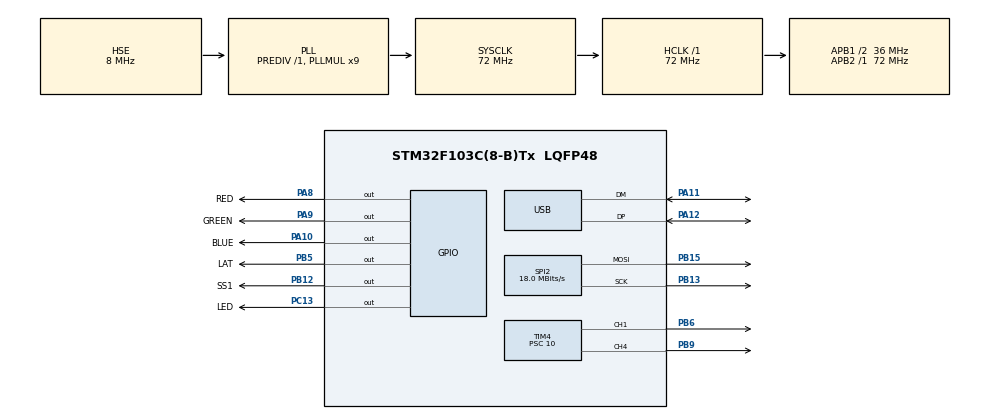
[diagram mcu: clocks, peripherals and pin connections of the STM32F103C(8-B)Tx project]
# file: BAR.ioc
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Dma.MEMTOMEM.0.Direction=DMA_MEMORY_TO_MEMORY
Dma.MEMTOMEM.0.Instance=DMA1_Channel6
Dma.MEMTOMEM.0.MemDataAlignment=DMA_MDATAALIGN_BYTE
Dma.MEMTOMEM.0.MemInc=DMA_MINC_ENABLE
Dma.MEMTOMEM.0.Mode=DMA_NORMAL
Dma.MEMTOMEM.0.PeriphDataAlignment=DMA_PDATAALIGN_BYTE
Dma.MEMTOMEM.0.PeriphInc=DMA_PINC_ENABLE
Dma.MEMTOMEM.0.Priority=DMA_PRIORITY_LOW
Dma.MEMTOMEM.1.Direction=DMA_MEMORY_TO_MEMORY
Dma.MEMTOMEM.1.Instance=DMA1_Channel4
Dma.MEMTOMEM.1.MemDataAlignment=DMA_MDATAALIGN_BYTE
Dma.MEMTOMEM.1.MemInc=DMA_MINC_ENABLE
Dma.MEMTOMEM.1.Mode=DMA_NORMAL
Dma.MEMTOMEM.1.PeriphDataAlignment=DMA_PDATAALIGN_BYTE
Dma.MEMTOMEM.1.PeriphInc=DMA_PINC_ENABLE
Dma.MEMTOMEM.1.Priority=DMA_PRIORITY_LOW
Dma.MEMTOMEM.2.Direction=DMA_MEMORY_TO_MEMORY
Dma.MEMTOMEM.2.Instance=DMA1_Channel1
Dma.MEMTOMEM.2.MemDataAlignment=DMA_MDATAALIGN_BYTE
Dma.MEMTOMEM.2.MemInc=DMA_MINC_ENABLE
Dma.MEMTOMEM.2.Mode=DMA_NORMAL
Dma.MEMTOMEM.2.PeriphDataAlignment=DMA_PDATAALIGN_BYTE
Dma.MEMTOMEM.2.PeriphInc=DMA_PINC_ENABLE
Dma.MEMTOMEM.2.Priority=DMA_PRIORITY_LOW
Dma.MEMTOMEM.3.Direction=DMA_MEMORY_TO_MEMORY
Dma.MEMTOMEM.3.Instance=DMA1_Channel7
Dma.MEMTOMEM.3.MemDataAlignment=DMA_MDATAALIGN_BYTE
Dma.MEMTOMEM.3.MemInc=DMA_MINC_ENABLE
Dma.MEMTOMEM.3.Mode=DMA_NORMAL
Dma.MEMTOMEM.3.PeriphDataAlignment=DMA_PDATAALIGN_BYTE
Dma.MEMTOMEM.3.PeriphInc=DMA_PINC_ENABLE
Dma.MEMTOMEM.3.Priority=DMA_PRIORITY_LOW
Dma.Request0=MEMTOMEM
Dma.Request1=MEMTOMEM
Dma.Request2=MEMTOMEM
Dma.Request3=MEMTOMEM
Dma.Request4=SPI2_TX
Dma.SPI2_TX.4.Direction=DMA_MEMORY_TO_PERIPH
Dma.SPI2_TX.4.Instance=DMA1_Channel5
Dma.SPI2_TX.4.MemDataAlignment=DMA_MDATAALIGN_BYTE
Dma.SPI2_TX.4.MemInc=DMA_MINC_ENABLE
Dma.SPI2_TX.4.Mode=DMA_NORMAL
Dma.SPI2_TX.4.PeriphDataAlignment=DMA_PDATAALIGN_BYTE
Dma.SPI2_TX.4.PeriphInc=DMA_PINC_DISABLE
Dma.SPI2_TX.4.Priority=DMA_PRIORITY_VERY_HIGH
Mcu.Family=STM32F1
Mcu.Name=STM32F103C(8-B)Tx
Mcu.Package=LQFP48
NVIC.DMA1_Channel5_IRQn=true\:0\:0\:false\:false\:true\:false\:true
NVIC.PriorityGroup=NVIC_PRIORITYGROUP_4
NVIC.SPI2_IRQn=true\:0\:0\:false\:false\:true\:true\:true
NVIC.TIM2_IRQn=true\:1\:0\:true\:false\:true\:true\:true
NVIC.TIM3_IRQn=true\:3\:0\:true\:false\:true\:true\:true
NVIC.USB_LP_CAN1_RX0_IRQn=true\:2\:0\:true\:false\:true\:false\:true
PA10.GPIO_Label=BLUE
PA10.Signal=GPIO_Output
PA11.Mode=Device
PA11.Signal=USB_DM
PA12.Mode=Device
PA12.Signal=USB_DP
PA13.Mode=Serial_Wire
PA13.Signal=SYS_JTMS-SWDIO
PA14.Mode=Serial_Wire
PA14.Signal=SYS_JTCK-SWCLK
PA8.GPIO_Label=RED
PA8.GPIO_PuPd=GPIO_PULLUP
PA8.GPIO_Speed=GPIO_SPEED_FREQ_HIGH
PA8.PinState=GPIO_PIN_RESET
PA8.Signal=GPIO_Output
PA9.GPIO_Label=GREEN
PA9.Signal=GPIO_Output
PB12.GPIO_Label=SS1
PB12.GPIO_PuPd=GPIO_PULLUP
PB12.Signal=GPIO_Output
PB13.Mode=TX_Only_Simplex_Unidirect_Master
PB13.Signal=SPI2_SCK
PB15.Mode=TX_Only_Simplex_Unidirect_Master
PB15.Signal=SPI2_MOSI
PB5.GPIO_Label=LAT
PB5.GPIO_PuPd=GPIO_PULLUP
PB5.GPIO_Speed=GPIO_SPEED_FREQ_LOW
PB5.Signal=GPIO_Output
PB6.Signal=S_TIM4_CH1
PB9.Signal=S_TIM4_CH4
PC13-TAMPER-RTC.GPIO_Label=LED
PC13-TAMPER-RTC.GPIO_PuPd=GPIO_PULLUP
PC13-TAMPER-RTC.PinState=GPIO_PIN_SET
PC13-TAMPER-RTC.Signal=GPIO_Output
PC14-OSC32_IN.Mode=LSE-External-Oscillator
PC14-OSC32_IN.Signal=RCC_OSC32_IN
PC15-OSC32_OUT.Mode=LSE-External-Oscillator
PC15-OSC32_OUT.Signal=RCC_OSC32_OUT
PD0-OSC_IN.Mode=HSE-External-Oscillator
PD0-OSC_IN.Signal=RCC_OSC_IN
PD1-OSC_OUT.Mode=HSE-External-Oscillator
PD1-OSC_OUT.Signal=RCC_OSC_OUT
ProjectManager.HeapSize=0x200
ProjectManager.StackSize=0x400
ProjectManager.TargetToolchain=STM32CubeIDE
RCC.AHBFreq_Value=72000000
RCC.APB1CLKDivider=RCC_HCLK_DIV2
RCC.APB1Freq_Value=36000000
RCC.APB1TimFreq_Value=72000000
RCC.APB2Freq_Value=72000000
RCC.APB2TimFreq_Value=72000000
RCC.HCLKFreq_Value=72000000
RCC.PLLMUL=RCC_PLL_MUL9
RCC.PLLSourceVirtual=RCC_PLLSOURCE_HSE
RCC.SYSCLKFreq_VALUE=72000000
RCC.SYSCLKSource=RCC_SYSCLKSOURCE_PLLCLK
RCC.USBFreq_Value=48000000
RCC.USBPrescaler=RCC_USBCLKSOURCE_PLL_DIV1_5
SH.S_TIM4_CH1.0=TIM4_CH1,PWM Generation1 CH1
SH.S_TIM4_CH4.0=TIM4_CH4,PWM Generation4 CH4
SPI2.CalculateBaudRate=18.0 MBits/s
SPI2.Direction=SPI_DIRECTION_2LINES
SPI2.Mode=SPI_MODE_MASTER
SPI2.VirtualType=VM_MASTER
TIM2.AutoReloadPreload=TIM_AUTORELOAD_PRELOAD_ENABLE
TIM2.ClockDivision=TIM_CLOCKDIVISION_DIV2
TIM2.Period=1366
TIM2.Prescaler=36
TIM3.AutoReloadPreload=TIM_AUTORELOAD_PRELOAD_ENABLE
TIM3.ClockDivision=TIM_CLOCKDIVISION_DIV2
TIM3.Period=10000
TIM3.Prescaler=3600
TIM4.AutoReloadPreload=TIM_AUTORELOAD_PRELOAD_DISABLE
TIM4.Channel-PWM\ Generation1\ CH1=TIM_CHANNEL_1
TIM4.Channel-PWM\ Generation4\ CH4=TIM_CHANNEL_4
TIM4.ClockDivision=TIM_CLOCKDIVISION_DIV2
TIM4.Period=254
TIM4.Prescaler=10
USB_DEVICE.CLASS_NAME_FS=CDC
USB_DEVICE.MANUFACTURER_STRING=dESIGNED bY @GiaLu 
USB_DEVICE.PRODUCT_STRING_CDC_FS=GiaLu
USB_DEVICE.VirtualMode=Cdc
USB_DEVICE.VirtualModeFS=Cdc_FS
VP_TIM2_VS_ClockSourceINT.Mode=Internal
VP_TIM3_VS_ClockSourceINT.Mode=Internal
VP_TIM4_VS_ClockSourceINT.Mode=Internal
VP_USB_DEVICE_VS_USB_DEVICE_CDC_FS.Mode=CDC_FS
board=custom

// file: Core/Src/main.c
/* USER CODE BEGIN Header */
/**
  ******************************************************************************
  * @file           : main.c
  * @brief          : Main program body
  ******************************************************************************
  * @attention
  *
  * <h2><center>&copy; Copyright (c) 2021 STMicroelectronics.
  * All rights reserved.</center></h2>
  *
  * This software component is licensed by ST under BSD 3-Clause license,
  * the "License"; You may not use this file except in compliance with the
  * License. You may obtain a copy of the License at:
  *                        opensource.org/licenses/BSD-3-Clause
  *
  ******************************************************************************
  */
/* USER CODE END Header */
#include "main.h"
#include "usb_device.h"

/* USER CODE BEGIN Includes */
#include "bar.h"
/* USER CODE END Includes */

SPI_HandleTypeDef hspi2;
DMA_HandleTypeDef hdma_spi2_tx;

TIM_HandleTypeDef htim2;
TIM_HandleTypeDef htim3;
TIM_HandleTypeDef htim4;

DMA_HandleTypeDef hdma_memtomem_dma1_channel6;
DMA_HandleTypeDef hdma_memtomem_dma1_channel4;
DMA_HandleTypeDef hdma_memtomem_dma1_channel1;
DMA_HandleTypeDef hdma_memtomem_dma1_channel7;

void SystemClock_Config(void);
static void MX_GPIO_Init(void);
static void MX_DMA_Init(void);
static void MX_SPI2_Init(void);
static void MX_TIM2_Init(void);
static void MX_TIM3_Init(void);
static void MX_TIM4_Init(void);

int main(void)
{

  /* MCU Configuration--------------------------------------------------------*/

  /* Reset of all peripherals, Initializes the Flash interface and the Systick. */
  HAL_Init();

  /* Configure the system clock */
  SystemClock_Config();

  /* Initialize all configured peripherals */
  MX_GPIO_Init();
  MX_DMA_Init();
  MX_SPI2_Init();
  MX_TIM2_Init();
  MX_TIM3_Init();
  MX_TIM4_Init();
  MX_USB_DEVICE_Init();

  /* Infinite loop */
  while (1)
  {

    /* USER CODE BEGIN 3 */

	  _run();
  }
  /* USER CODE END 3 */
}

void SystemClock_Config(void)
{
  RCC_OscInitTypeDef RCC_OscInitStruct = {0};
  RCC_ClkInitTypeDef RCC_ClkInitStruct = {0};
  RCC_PeriphCLKInitTypeDef PeriphClkInit = {0};

  /** Initializes the RCC Oscillators according to the specified parameters
  * in the RCC_OscInitTypeDef structure.
  */
  RCC_OscInitStruct.OscillatorType = RCC_OSCILLATORTYPE_HSE;
  RCC_OscInitStruct.HSEState = RCC_HSE_ON;
  RCC_OscInitStruct.HSEPredivValue = RCC_HSE_PREDIV_DIV1;
  RCC_OscInitStruct.HSIState = RCC_HSI_ON;
  RCC_OscInitStruct.PLL.PLLState = RCC_PLL_ON;
  RCC_OscInitStruct.PLL.PLLSource = RCC_PLLSOURCE_HSE;
  RCC_OscInitStruct.PLL.PLLMUL = RCC_PLL_MUL9;
  if (HAL_RCC_OscConfig(&RCC_OscInitStruct) != HAL_OK)
  {
    Error_Handler();
  }
  /** Initializes the CPU, AHB and APB buses clocks
  */
  RCC_ClkInitStruct.ClockType = RCC_CLOCKTYPE_HCLK|RCC_CLOCKTYPE_SYSCLK
                              |RCC_CLOCKTYPE_PCLK1|RCC_CLOCKTYPE_PCLK2;
  RCC_ClkInitStruct.SYSCLKSource = RCC_SYSCLKSOURCE_PLLCLK;
  RCC_ClkInitStruct.AHBCLKDivider = RCC_SYSCLK_DIV1;
  RCC_ClkInitStruct.APB1CLKDivider = RCC_HCLK_DIV2;
  RCC_ClkInitStruct.APB2CLKDivider = RCC_HCLK_DIV1;

  if (HAL_RCC_ClockConfig(&RCC_ClkInitStruct, FLASH_LATENCY_2) != HAL_OK)
  {
    Error_Handler();
  }
  PeriphClkInit.PeriphClockSelection = RCC_PERIPHCLK_USB;
  PeriphClkInit.UsbClockSelection = RCC_USBCLKSOURCE_PLL_DIV1_5;
  if (HAL_RCCEx_PeriphCLKConfig(&PeriphClkInit) != HAL_OK)
  {
    Error_Handler();
  }
}

static void MX_SPI2_Init(void)
{

  /* SPI2 parameter configuration*/
  hspi2.Instance = SPI2;
  hspi2.Init.Mode = SPI_MODE_MASTER;
  hspi2.Init.Direction = SPI_DIRECTION_2LINES;
  hspi2.Init.DataSize = SPI_DATASIZE_8BIT;
  hspi2.Init.CLKPolarity = SPI_POLARITY_LOW;
  hspi2.Init.CLKPhase = SPI_PHASE_1EDGE;
  hspi2.Init.NSS = SPI_NSS_SOFT;
  hspi2.Init.BaudRatePrescaler = SPI_BAUDRATEPRESCALER_2;
  hspi2.Init.FirstBit = SPI_FIRSTBIT_MSB;
  hspi2.Init.TIMode = SPI_TIMODE_DISABLE;
  hspi2.Init.CRCCalculation = SPI_CRCCALCULATION_DISABLE;
  hspi2.Init.CRCPolynomial = 10;
  if (HAL_SPI_Init(&hspi2) != HAL_OK)
  {
    Error_Handler();
  }

}

static void MX_TIM2_Init(void)
{

  TIM_ClockConfigTypeDef sClockSourceConfig = {0};
  TIM_MasterConfigTypeDef sMasterConfig = {0};

  htim2.Instance = TIM2;
  htim2.Init.Prescaler = 36;
  htim2.Init.CounterMode = TIM_COUNTERMODE_UP;
  htim2.Init.Period = 1366;
  htim2.Init.ClockDivision = TIM_CLOCKDIVISION_DIV2;
  htim2.Init.AutoReloadPreload = TIM_AUTORELOAD_PRELOAD_ENABLE;
  if (HAL_TIM_Base_Init(&htim2) != HAL_OK)
  {
    Error_Handler();
  }
  sClockSourceConfig.ClockSource = TIM_CLOCKSOURCE_INTERNAL;
  if (HAL_TIM_ConfigClockSource(&htim2, &sClockSourceConfig) != HAL_OK)
  {
    Error_Handler();
  }
  sMasterConfig.MasterOutputTrigger = TIM_TRGO_RESET;
  sMasterConfig.MasterSlaveMode = TIM_MASTERSLAVEMODE_DISABLE;
  if (HAL_TIMEx_MasterConfigSynchronization(&htim2, &sMasterConfig) != HAL_OK)
  {
    Error_Handler();
  }

}

static void MX_TIM3_Init(void)
{

  TIM_ClockConfigTypeDef sClockSourceConfig = {0};
  TIM_MasterConfigTypeDef sMasterConfig = {0};

  htim3.Instance = TIM3;
  htim3.Init.Prescaler = 3600;
  htim3.Init.CounterMode = TIM_COUNTERMODE_UP;
  htim3.Init.Period = 10000;
  htim3.Init.ClockDivision = TIM_CLOCKDIVISION_DIV2;
  htim3.Init.AutoReloadPreload = TIM_AUTORELOAD_PRELOAD_ENABLE;
  if (HAL_TIM_Base_Init(&htim3) != HAL_OK)
  {
    Error_Handler();
  }
  sClockSourceConfig.ClockSource = TIM_CLOCKSOURCE_INTERNAL;
  if (HAL_TIM_ConfigClockSource(&htim3, &sClockSourceConfig) != HAL_OK)
  {
    Error_Handler();
  }
  sMasterConfig.MasterOutputTrigger = TIM_TRGO_RESET;
  sMasterConfig.MasterSlaveMode = TIM_MASTERSLAVEMODE_DISABLE;
  if (HAL_TIMEx_MasterConfigSynchronization(&htim3, &sMasterConfig) != HAL_OK)
  {
    Error_Handler();
  }

}

static void MX_TIM4_Init(void)
{

  TIM_ClockConfigTypeDef sClockSourceConfig = {0};
  TIM_MasterConfigTypeDef sMasterConfig = {0};
  TIM_OC_InitTypeDef sConfigOC = {0};

  htim4.Instance = TIM4;
  htim4.Init.Prescaler = 10;
  htim4.Init.CounterMode = TIM_COUNTERMODE_UP;
  htim4.Init.Period = 254;
  htim4.Init.ClockDivision = TIM_CLOCKDIVISION_DIV2;
  htim4.Init.AutoReloadPreload = TIM_AUTORELOAD_PRELOAD_DISABLE;
  if (HAL_TIM_Base_Init(&htim4) != HAL_OK)
  {
    Error_Handler();
  }
  sClockSourceConfig.ClockSource = TIM_CLOCKSOURCE_INTERNAL;
  if (HAL_TIM_ConfigClockSource(&htim4, &sClockSourceConfig) != HAL_OK)
  {
    Error_Handler();
  }
  if (HAL_TIM_PWM_Init(&htim4) != HAL_OK)
  {
    Error_Handler();
  }
  sMasterConfig.MasterOutputTrigger = TIM_TRGO_RESET;
  sMasterConfig.MasterSlaveMode = TIM_MASTERSLAVEMODE_DISABLE;
  if (HAL_TIMEx_MasterConfigSynchronization(&htim4, &sMasterConfig) != HAL_OK)
  {
    Error_Handler();
  }
  sConfigOC.OCMode = TIM_OCMODE_PWM1;
  sConfigOC.Pulse = 0;
  sConfigOC.OCPolarity = TIM_OCPOLARITY_HIGH;
  sConfigOC.OCFastMode = TIM_OCFAST_DISABLE;
  if (HAL_TIM_PWM_ConfigChannel(&htim4, &sConfigOC, TIM_CHANNEL_1) != HAL_OK)
  {
    Error_Handler();
  }
  if (HAL_TIM_PWM_ConfigChannel(&htim4, &sConfigOC, TIM_CHANNEL_4) != HAL_OK)
  {
    Error_Handler();
  }
  HAL_TIM_MspPostInit(&htim4);

}

static void MX_DMA_Init(void)
{

  /* DMA controller clock enable */
  __HAL_RCC_DMA1_CLK_ENABLE();

  /* Configure DMA request hdma_memtomem_dma1_channel6 on DMA1_Channel6 */
  hdma_memtomem_dma1_channel6.Instance = DMA1_Channel6;
  hdma_memtomem_dma1_channel6.Init.Direction = DMA_MEMORY_TO_MEMORY;
  hdma_memtomem_dma1_channel6.Init.PeriphInc = DMA_PINC_ENABLE;
  hdma_memtomem_dma1_channel6.Init.MemInc = DMA_MINC_ENABLE;
  hdma_memtomem_dma1_channel6.Init.PeriphDataAlignment = DMA_PDATAALIGN_BYTE;
  hdma_memtomem_dma1_channel6.Init.MemDataAlignment = DMA_MDATAALIGN_BYTE;
  hdma_memtomem_dma1_channel6.Init.Mode = DMA_NORMAL;
  hdma_memtomem_dma1_channel6.Init.Priority = DMA_PRIORITY_LOW;
  if (HAL_DMA_Init(&hdma_memtomem_dma1_channel6) != HAL_OK)
  {
    Error_Handler( );
  }

  /* Configure DMA request hdma_memtomem_dma1_channel4 on DMA1_Channel4 */
  hdma_memtomem_dma1_channel4.Instance = DMA1_Channel4;
  hdma_memtomem_dma1_channel4.Init.Direction = DMA_MEMORY_TO_MEMORY;
  hdma_memtomem_dma1_channel4.Init.PeriphInc = DMA_PINC_ENABLE;
  hdma_memtomem_dma1_channel4.Init.MemInc = DMA_MINC_ENABLE;
  hdma_memtomem_dma1_channel4.Init.PeriphDataAlignment = DMA_PDATAALIGN_BYTE;
  hdma_memtomem_dma1_channel4.Init.MemDataAlignment = DMA_MDATAALIGN_BYTE;
  hdma_memtomem_dma1_channel4.Init.Mode = DMA_NORMAL;
  hdma_memtomem_dma1_channel4.Init.Priority = DMA_PRIORITY_LOW;
  if (HAL_DMA_Init(&hdma_memtomem_dma1_channel4) != HAL_OK)
  {
    Error_Handler( );
  }

  /* Configure DMA request hdma_memtomem_dma1_channel1 on DMA1_Channel1 */
  hdma_memtomem_dma1_channel1.Instance = DMA1_Channel1;
  hdma_memtomem_dma1_channel1.Init.Direction = DMA_MEMORY_TO_MEMORY;
  hdma_memtomem_dma1_channel1.Init.PeriphInc = DMA_PINC_ENABLE;
  hdma_memtomem_dma1_channel1.Init.MemInc = DMA_MINC_ENABLE;
  hdma_memtomem_dma1_channel1.Init.PeriphDataAlignment = DMA_PDATAALIGN_BYTE;
  hdma_memtomem_dma1_channel1.Init.MemDataAlignment = DMA_MDATAALIGN_BYTE;
  hdma_memtomem_dma1_channel1.Init.Mode = DMA_NORMAL;
  hdma_memtomem_dma1_channel1.Init.Priority = DMA_PRIORITY_LOW;
  if (HAL_DMA_Init(&hdma_memtomem_dma1_channel1) != HAL_OK)
  {
    Error_Handler( );
  }

  /* Configure DMA request hdma_memtomem_dma1_channel7 on DMA1_Channel7 */
  hdma_memtomem_dma1_channel7.Instance = DMA1_Channel7;
  hdma_memtomem_dma1_channel7.Init.Direction = DMA_MEMORY_TO_MEMORY;
  hdma_memtomem_dma1_channel7.Init.PeriphInc = DMA_PINC_ENABLE;
  hdma_memtomem_dma1_channel7.Init.MemInc = DMA_MINC_ENABLE;
  hdma_memtomem_dma1_channel7.Init.PeriphDataAlignment = DMA_PDATAALIGN_BYTE;
  hdma_memtomem_dma1_channel7.Init.MemDataAlignment = DMA_MDATAALIGN_BYTE;
  hdma_memtomem_dma1_channel7.Init.Mode = DMA_NORMAL;
  hdma_memtomem_dma1_channel7.Init.Priority = DMA_PRIORITY_LOW;
  if (HAL_DMA_Init(&hdma_memtomem_dma1_channel7) != HAL_OK)
  {
    Error_Handler( );
  }

  /* DMA interrupt init */
  /* DMA1_Channel5_IRQn interrupt configuration */
  HAL_NVIC_SetPriority(DMA1_Channel5_IRQn, 0, 0);
  HAL_NVIC_EnableIRQ(DMA1_Channel5_IRQn);

}

static void MX_GPIO_Init(void)
{
  GPIO_InitTypeDef GPIO_InitStruct = {0};

  /* GPIO Ports Clock Enable */
  __HAL_RCC_GPIOC_CLK_ENABLE();
  __HAL_RCC_GPIOD_CLK_ENABLE();
  __HAL_RCC_GPIOB_CLK_ENABLE();
  __HAL_RCC_GPIOA_CLK_ENABLE();

  /*Configure GPIO pin Output Level */
  HAL_GPIO_WritePin(LED_GPIO_Port, LED_Pin, GPIO_PIN_SET);

  /*Configure GPIO pin Output Level */
  HAL_GPIO_WritePin(GPIOB, SS1_Pin|LAT_Pin, GPIO_PIN_RESET);

  /*Configure GPIO pin Output Level */
  HAL_GPIO_WritePin(GPIOA, RED_Pin|GREEN_Pin|BLUE_Pin, GPIO_PIN_RESET);

  /*Configure GPIO pin : LED_Pin */
  GPIO_InitStruct.Pin = LED_Pin;
  GPIO_InitStruct.Mode = GPIO_MODE_OUTPUT_PP;
  GPIO_InitStruct.Pull = GPIO_PULLUP;
  GPIO_InitStruct.Speed = GPIO_SPEED_FREQ_LOW;
  HAL_GPIO_Init(LED_GPIO_Port, &GPIO_InitStruct);

  /*Configure GPIO pins : SS1_Pin LAT_Pin */
  GPIO_InitStruct.Pin = SS1_Pin|LAT_Pin;
  GPIO_InitStruct.Mode = GPIO_MODE_OUTPUT_PP;
  GPIO_InitStruct.Pull = GPIO_PULLUP;
  GPIO_InitStruct.Speed = GPIO_SPEED_FREQ_LOW;
  HAL_GPIO_Init(GPIOB, &GPIO_InitStruct);

  /*Configure GPIO pin : RED_Pin */
  GPIO_InitStruct.Pin = RED_Pin;
  GPIO_InitStruct.Mode = GPIO_MODE_OUTPUT_PP;
  GPIO_InitStruct.Pull = GPIO_PULLUP;
  GPIO_InitStruct.Speed = GPIO_SPEED_FREQ_HIGH;
  HAL_GPIO_Init(RED_GPIO_Port, &GPIO_InitStruct);

  /*Configure GPIO pins : GREEN_Pin BLUE_Pin */
  GPIO_InitStruct.Pin = GREEN_Pin|BLUE_Pin;
  GPIO_InitStruct.Mode = GPIO_MODE_OUTPUT_PP;
  GPIO_InitStruct.Pull = GPIO_NOPULL;
  GPIO_InitStruct.Speed = GPIO_SPEED_FREQ_LOW;
  HAL_GPIO_Init(GPIOA, &GPIO_InitStruct);

}

void Error_Handler(void)
{
  /* USER CODE BEGIN Error_Handler_Debug */
  /* User can add his own implementation to report the HAL error return state */
  __disable_irq();

  while (1)
  {

	  brigthness(1);

  }
  /* USER CODE END Error_Handler_Debug */
}

/************************ (C) COPYRIGHT STMicroelectronics *****END OF FILE****/
